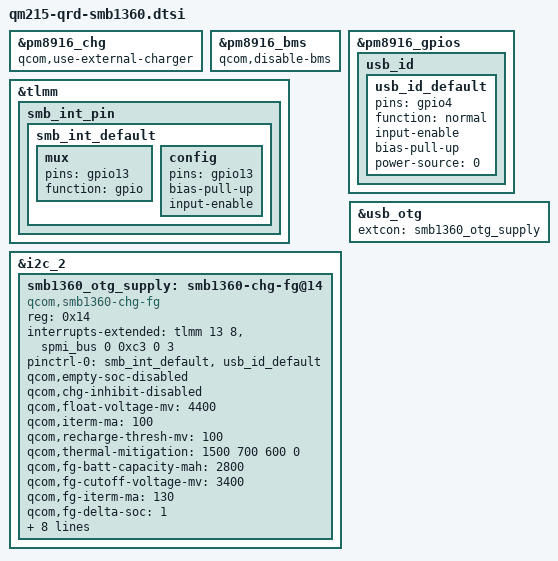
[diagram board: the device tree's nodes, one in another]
/* Copyright (c) 2019, The Linux Foundation. All rights reserved.
 *
 * This program is free software; you can redistribute it and/or modify
 * it under the terms of the GNU General Public License version 2 and
 * only version 2 as published by the Free Software Foundation.
 *
 * This program is distributed in the hope that it will be useful,
 * but WITHOUT ANY WARRANTY; without even the implied warranty of
 * MERCHANTABILITY or FITNESS FOR A PARTICULAR PURPOSE.  See the
 * GNU General Public License for more details.
 */

#include "qm215-qrd.dtsi"

&pm8916_chg{
	qcom,use-external-charger;
};

&pm8916_bms{
	qcom,disable-bms;
};

&tlmm {
		/* SMB interrupt pin */
		smb_int_pin {
			smb_int_default: smb_int_default {
				mux {
					pins = "gpio13";
					function ="gpio";
				};
				config {
					pins = "gpio13";
					bias-pull-up;           /* PULL UP*/
					input-enable;
				};
			};
		};
};

&pm8916_gpios {
	usb_id {
		usb_id_default: usb_id_default {
			pins = "gpio4";
			function = "normal";
			input-enable;
			bias-pull-up;
			power-source = <0>;
		};
	};
};

&i2c_2 {
	status ="ok";
	smb1360_otg_supply: smb1360-chg-fg@14 {
		compatible = "qcom,smb1360-chg-fg";
		reg = <0x14>;
		interrupts-extended = <&tlmm 13 8>,
				<&spmi_bus 0 0xc3 0 3>;
		interrupt-names = "smb1360_stat_irq",
				"smb1360_usb_id_irq";
		pinctrl-names = "default";
		pinctrl-0 = <&smb_int_default>,
			<&usb_id_default>;
		qcom,empty-soc-disabled;
		qcom,chg-inhibit-disabled;
		qcom,float-voltage-mv = <4400>;
		qcom,iterm-ma = <100>;
		qcom,recharge-thresh-mv = <100>;
		qcom,thermal-mitigation = <1500 700 600 0>;
		qcom,fg-batt-capacity-mah = <2800>;
		qcom,fg-cutoff-voltage-mv = <3400>;
		qcom,fg-iterm-ma = <130>;
		qcom,fg-delta-soc = <1>;
		qcom,usb-id-gpio = <&pm8916_gpios 4 0>;
		qcom,soft-jeita-supported;
		qcom,warm-bat-decidegc = <450>;
		qcom,cool-bat-decidegc = <150>;
		qcom,warm-bat-mv = <4200>;
		qcom,cool-bat-mv = <4200>;
		qcom,warm-bat-ma = <1000>;
		qcom,cool-bat-ma = <1000>;
		status= "okay";
	};
};

&usb_otg {
	extcon = <&smb1360_otg_supply>;
};
